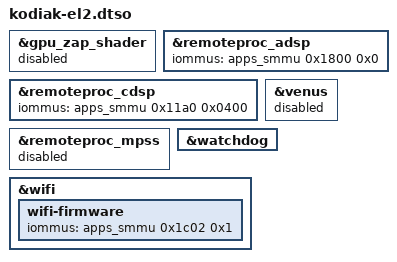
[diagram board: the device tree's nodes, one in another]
// SPDX-License-Identifier: BSD-3-Clause
/*
 * Copyright (c) Qualcomm Technologies, Inc. and/or its subsidiaries.
 *
 * Kodiak specific modifications required to boot in EL2.
 */

/dts-v1/;
/plugin/;

&gpu_zap_shader {
	status = "disabled";
};

&remoteproc_adsp {
	iommus = <&apps_smmu 0x1800 0x0>;
};

&remoteproc_cdsp {
	iommus = <&apps_smmu 0x11a0 0x0400>;
};

&remoteproc_mpss {
	status = "disabled";
};

&venus {
	status = "disabled";
};

&watchdog {
	status = "okay";
};

&wifi {
	wifi-firmware {
		iommus = <&apps_smmu 0x1c02 0x1>;
	};
};
